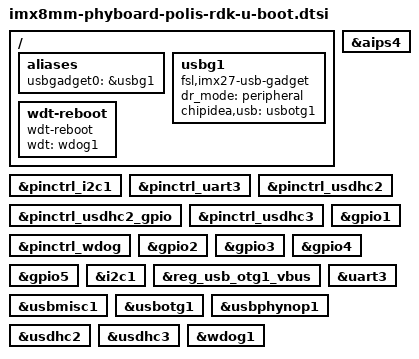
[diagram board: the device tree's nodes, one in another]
// SPDX-License-Identifier: GPL-2.0-or-later
/*
 * Copyright (C) 2020 PHYTEC Messtechnik GmbH
 * Author: Teresa Remmet <t.remmet@phytec.de>
 */

#include "imx8mm-u-boot.dtsi"

/ {
	aliases {
		usbgadget0 = &usbg1;
	};

	usbg1: usbg1 {
		compatible = "fsl,imx27-usb-gadget";
		dr_mode = "peripheral";
		chipidea,usb = <&usbotg1>;
		status = "okay";
	};

	wdt-reboot {
		compatible = "wdt-reboot";
		wdt = <&wdog1>;
		bootph-pre-ram;
	};
};

&aips4 {
	bootph-pre-ram;
};

&pinctrl_i2c1 {
	bootph-pre-ram;
};

&pinctrl_uart3 {
	bootph-pre-ram;
};

&pinctrl_usdhc2_gpio {
	bootph-pre-ram;
};

&pinctrl_usdhc2 {
	bootph-pre-ram;
};

&pinctrl_usdhc3 {
	bootph-pre-ram;
};

&pinctrl_wdog {
	bootph-pre-ram;
};

&gpio1 {
	bootph-pre-ram;
};

&gpio2 {
	bootph-pre-ram;
};

&gpio3 {
	bootph-pre-ram;
};

&gpio4 {
	bootph-pre-ram;
};

&gpio5 {
	bootph-pre-ram;
};

&i2c1 {
	bootph-pre-ram;
};

&reg_usb_otg1_vbus {
	bootph-pre-ram;
};

&uart3 {
	bootph-pre-ram;
};

&usbmisc1 {
	bootph-pre-ram;
};

&usbotg1 {
	bootph-pre-ram;
};

&usbphynop1 {
	bootph-pre-ram;
};

&usdhc2 {
	bootph-pre-ram;
};

&usdhc3 {
	bootph-pre-ram;
};

&wdog1 {
	bootph-pre-ram;
};
